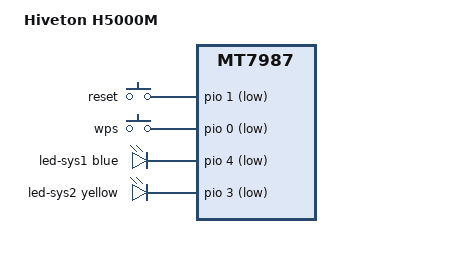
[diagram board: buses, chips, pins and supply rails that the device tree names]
// SPDX-License-Identifier: (GPL-2.0 OR MIT)
/*
 * Copyright (C) 2025 MediaTek Inc.
 * Author: Sam.Shih <sam.shih@mediatek.com>
 */

/dts-v1/;
#include "mt7987a.dtsi"
#include <dt-bindings/input/input.h>
#include "mt7987-emmc.dtsi"

/* MT7987A RFB DTS for DT overlay-based device tree */
/ {
	model = "Hiveton H5000M";
	compatible = "hiveton,h5000m", "mediatek,mt7987";

	chosen {
		bootargs = "console=ttyS0,115200n1 loglevel=8  \
                            earlycon=uart8250,mmio32,0x11000000 \
                            pci=pcie_bus_perf \
			    root=PARTLABEL=rootfs rootwait \
			    rootfstype=squashfs,f2fs";
	};

	gpio-keys {
		compatible = "gpio-keys";

		reset {
			label = "reset";
			linux,code = <KEY_RESTART>;
			gpios = <&pio 1 GPIO_ACTIVE_LOW>;
			debounce-interval = <10>;
		};

		wps {
			label = "wps";
			linux,code = <KEY_WPS_BUTTON>;
			gpios = <&pio 0 GPIO_ACTIVE_LOW>;
			debounce-interval = <10>;
		};
	};

	leds {
		compatible = "gpio-leds";

		led-sys1 {
			gpios = <&pio 4 GPIO_ACTIVE_LOW>;
			color = <LED_COLOR_ID_BLUE>;
			function = LED_FUNCTION_POWER;
		};

		led-sys2 {
			gpios = <&pio 3 GPIO_ACTIVE_LOW>;
			color = <LED_COLOR_ID_YELLOW>;
			function = LED_FUNCTION_POWER;
		};
	};
};

